AUTOSAR XML (schema 00046)
package /ComponentTypes
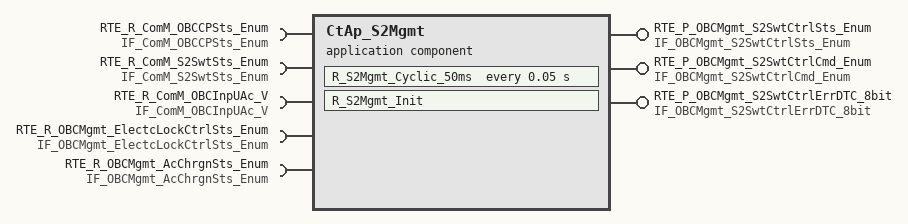
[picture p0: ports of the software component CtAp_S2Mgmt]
  application sw component type CtAp_S2Mgmt
    provide port RTE_P_OBCMgmt_S2SwtCtrlSts_Enum: nonqueued-sender-com-spec{data-element=tec_OBCMgmt_S2SwtCtrlSts_Enum, init-value=0}, provided-interface=IF_OBCMgmt_S2SwtCtrlSts_Enum
    provide port RTE_P_OBCMgmt_S2SwtCtrlCmd_Enum: nonqueued-sender-com-spec{data-element=tec_OBCMgmt_S2SwtCtrlCmd_Enum, init-value=0}, provided-interface=IF_OBCMgmt_S2SwtCtrlCmd_Enum
    provide port RTE_P_OBCMgmt_S2SwtCtrlErrDTC_8bit: nonqueued-sender-com-spec{data-element=tec_OBCMgmt_S2SwtCtrlErrDTC_8bit, init-value=0}, provided-interface=IF_OBCMgmt_S2SwtCtrlErrDTC_8bit
    5 x require port:
      RTE_R_ComM_OBCCPSts_Enum: nonqueued-receiver-com-spec{data-element=tec_ComM_OBCCPSts_Enum, filter=data-filter-type=ALWAYS, init-value=0}, required-interface=IF_ComM_OBCCPSts_Enum
      RTE_R_ComM_S2SwtSts_Enum: nonqueued-receiver-com-spec{data-element=tec_ComM_S2SwtSts_Enum, filter=data-filter-type=ALWAYS, init-value=0}, required-interface=IF_ComM_S2SwtSts_Enum
      RTE_R_ComM_OBCInpUAc_V: nonqueued-receiver-com-spec{data-element=tec_ComM_OBCInpUAc_V, filter=data-filter-type=ALWAYS, init-value=0}, required-interface=IF_ComM_OBCInpUAc_V
      RTE_R_OBCMgmt_ElectcLockCtrlSts_Enum: nonqueued-receiver-com-spec{data-element=tec_OBCMgmt_ElectcLockCtrlSts_Enum, filter=data-filter-type=ALWAYS, init-value=0}, required-interface=IF_OBCMgmt_ElectcLockCtrlSts_Enum
      RTE_R_OBCMgmt_AcChrgnSts_Enum: nonqueued-receiver-com-spec{data-element=tec_OBCMgmt_AcChrgnSts_Enum, filter=data-filter-type=ALWAYS, init-value=0}, required-interface=IF_OBCMgmt_AcChrgnSts_Enum
    behavior CtAp_S2Mgmt_InternalBehavior
      init event CtAp_S2Mgmt_InitEvent: start-on-event=R_S2Mgmt_Init
      timing event TMT_R_S2Mgmt_Cyclic_50ms: start-on-event=R_S2Mgmt_Cyclic_50ms, period=0.05
      runnable R_S2Mgmt_Init
      runnable R_S2Mgmt_Cyclic_50ms
        data-receive-point-by-arguments:
          5 x access:
            REC_RTE_R_ComM_OBCCPSts_Enum_tec_ComM_OBCCPSts_Enum: accessed-variable=RTE_R_ComM_OBCCPSts_Enum.tec_ComM_OBCCPSts_Enum
            REC_RTE_R_ComM_OBCInpUAc_V_tec_ComM_OBCInpUAc_V: accessed-variable=RTE_R_ComM_OBCInpUAc_V.tec_ComM_OBCInpUAc_V
            REC_RTE_R_ComM_S2SwtSts_Enum_tec_ComM_S2SwtSts_Enum: accessed-variable=RTE_R_ComM_S2SwtSts_Enum.tec_ComM_S2SwtSts_Enum
            REC_RTE_R_OBCMgmt_AcChrgnSts_Enum_tec_OBCMgmt_AcChrgnSts_Enum: accessed-variable=RTE_R_OBCMgmt_AcChrgnSts_Enum.tec_OBCMgmt_AcChrgnSts_Enum
            REC_RTE_R_OBCMgmt_ElectcLockCtrlSts_Enum_tec_OBCMgmt_ElectcLockCtrlSts_Enum: accessed-variable=RTE_R_OBCMgmt_ElectcLockCtrlSts_Enum.tec_OBCMgmt_ElectcLockCtrlSts_Enum
        data-send-points:
          access SEND_RTE_P_OBCMgmt_S2SwtCtrlCmd_Enum_tec_OBCMgmt_S2SwtCtrlCmd_Enum: accessed-variable=RTE_P_OBCMgmt_S2SwtCtrlCmd_Enum.tec_OBCMgmt_S2SwtCtrlCmd_Enum
          access SEND_RTE_P_OBCMgmt_S2SwtCtrlErrDTC_8bit_tec_OBCMgmt_S2SwtCtrlErrDTC_8bit: accessed-variable=RTE_P_OBCMgmt_S2SwtCtrlErrDTC_8bit.tec_OBCMgmt_S2SwtCtrlErrDTC_8bit
          access SEND_RTE_P_OBCMgmt_S2SwtCtrlSts_Enum_tec_OBCMgmt_S2SwtCtrlSts_Enum: accessed-variable=RTE_P_OBCMgmt_S2SwtCtrlSts_Enum.tec_OBCMgmt_S2SwtCtrlSts_Enum
  swc implementation CtAp_S2Mgmt_Implementation: behavior=CtAp_S2Mgmt_InternalBehavior
    code-descriptors:
      code Default: artifact-descriptors=autosar-engineering-object=category=SWOBJ
